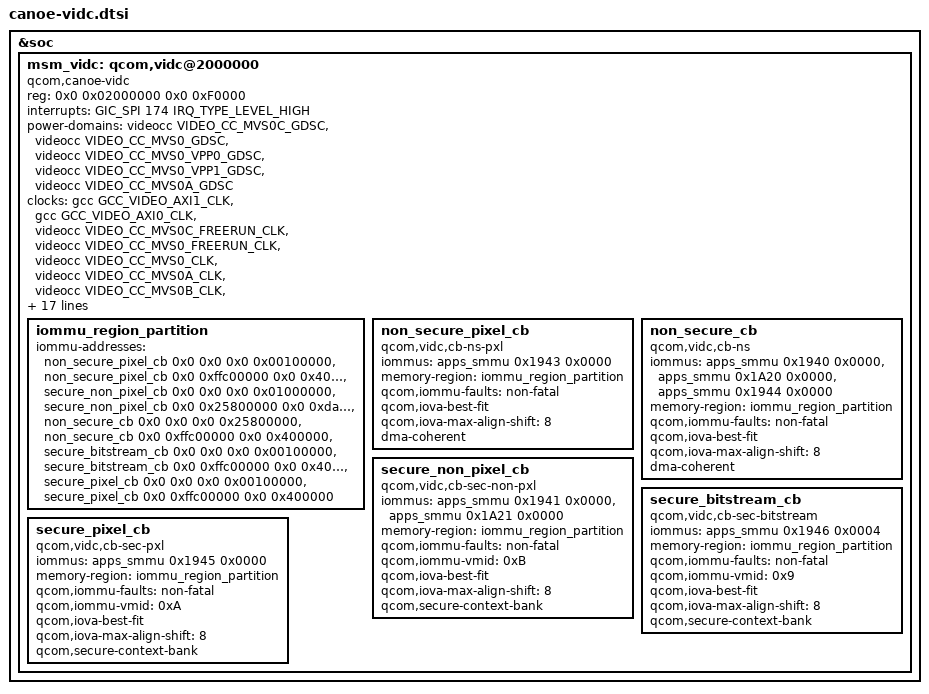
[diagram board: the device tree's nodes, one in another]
// SPDX-License-Identifier: BSD-3-Clause
/*
 * Copyright (c) 2024-2025 Qualcomm Innovation Center, Inc. All rights reserved.
 */

&soc {
	msm_vidc: qcom,vidc@2000000 {
		compatible = "qcom,canoe-vidc";
		status = "okay";

		/* IOMMU Config */
		#address-cells = <2>;
		#size-cells    = <2>;

		reg = <0x0 0x02000000 0x0 0xF0000>;
		interrupts = <GIC_SPI 174 IRQ_TYPE_LEVEL_HIGH>;

		/* Power Domains */
		power-domains = <&videocc VIDEO_CC_MVS0C_GDSC>,
				<&videocc VIDEO_CC_MVS0_GDSC>,
				<&videocc VIDEO_CC_MVS0_VPP0_GDSC>,
				<&videocc VIDEO_CC_MVS0_VPP1_GDSC>,
				<&videocc VIDEO_CC_MVS0A_GDSC>;
		power-domain-names = "iris-ctl", "vcodec", "vpp0", "vpp1", "apv";

		/* Clocks */
		clocks =
			 <&gcc GCC_VIDEO_AXI1_CLK>,
			 <&gcc GCC_VIDEO_AXI0_CLK>,
			 <&videocc VIDEO_CC_MVS0C_FREERUN_CLK>,
			 <&videocc VIDEO_CC_MVS0_FREERUN_CLK>,
			 <&videocc VIDEO_CC_MVS0_CLK>,
			 <&videocc VIDEO_CC_MVS0A_CLK>,
			 <&videocc VIDEO_CC_MVS0B_CLK>,
			 <&videocc VIDEO_CC_MVS0C_CLK>,
			 <&videocc VIDEO_CC_MVS0_VPP0_CLK>,
			 <&videocc VIDEO_CC_MVS0_VPP1_CLK>,
			 <&videocc VIDEO_CC_MVS0_CLK_SRC>,
			 <&videocc VIDEO_CC_MVS0A_CLK_SRC>,
			 <&videocc VIDEO_CC_MVS0B_CLK_SRC>,
			 <&videocc VIDEO_CC_MVS0C_CLK_SRC>;
		clock-names =
			 "gcc_video_axi1_clk",
			 "gcc_video_axi0_clk",
			 "video_cc_mvs0c_freerun_clk",
			 "video_cc_mvs0_freerun_clk",
			 "video_cc_mvs0_clk",
			 "video_cc_mvs0a_clk",
			 "video_cc_mvs0b_clk",
			 "video_cc_mvs0c_clk",
			 "video_cc_mvs0_vpp0_clk",
			 "video_cc_mvs0_vpp1_clk",
			 "video_cc_mvs0_clk_src",
			 "video_cc_mvs0a_clk_src",
			 "video_cc_mvs0b_clk_src",
			 "video_cc_mvs0c_clk_src";

		/* Bus Interconnects */
		interconnects =
			 <&gem_noc MASTER_APPSS_PROC &config_noc SLAVE_VENUS_CFG>,
			 <&mc_virt MASTER_LLCC &mc_virt SLAVE_EBI1>,
			 <&mmss_noc MASTER_VIDEO_MVP &gem_noc SLAVE_LLCC>;
		interconnect-names =
			 "venus-cnoc",
			 "venus-ddr",
			 "venus-llcc";

		/* FW load region */
		memory-region = <&video_mem>;

		/* Clock Resets */
		resets =
			 <&gcc GCC_VIDEO_AXI1_CLK_ARES>,
			 <&gcc GCC_VIDEO_AXI0_CLK_ARES>,
			 <&videocc VIDEO_CC_MVS0C_FREERUN_CLK_ARES>,
			 <&videocc VIDEO_CC_MVS0_FREERUN_CLK_ARES>;
		reset-names =
			 "video_axi1_reset",
			 "video_axi0_reset",
			 "video_mvs0c_freerun_reset",
			 "video_mvs0_freerun_reset";

		/* MMUs */
		iommu_region_partition: iommu_region_partition {
			/* These IOVA regions are unique per context bank */
			iommu-addresses =
				<&non_secure_pixel_cb 0x0 0x0 0x0 0x00100000>,
					<&non_secure_pixel_cb 0x0 0xffc00000 0x0 0x400000>,
				<&secure_non_pixel_cb 0x0 0x0 0x0 0x01000000>,
					<&secure_non_pixel_cb 0x0 0x25800000 0x0 0xda800000>,
				<&non_secure_cb       0x0 0x0 0x0 0x25800000>,
					<&non_secure_cb       0x0 0xffc00000  0x0 0x400000>,
				<&secure_bitstream_cb 0x0 0x0 0x0 0x00100000>,
					<&secure_bitstream_cb 0x0 0xffc00000 0x0 0x400000>,
				<&secure_pixel_cb     0x0 0x0 0x0 0x00100000>,
					<&secure_pixel_cb     0x0 0xffc00000 0x0 0x400000>;
		};

		non_secure_pixel_cb: non_secure_pixel_cb {
			compatible = "qcom,vidc,cb-ns-pxl";
			iommus = <&apps_smmu 0x1943 0x0000>;
			memory-region = <&iommu_region_partition>;
			qcom,iommu-faults = "non-fatal";
			qcom,iova-best-fit;
			/* log2 of desired alignment (1MB) - log2 of PAGE_SIZE; (8 = 20 - 12) */
			qcom,iova-max-align-shift = <8>;
			dma-coherent;
		};

		non_secure_cb: non_secure_cb {
			compatible = "qcom,vidc,cb-ns";
			iommus = <&apps_smmu 0x1940 0x0000>,
				 <&apps_smmu 0x1A20 0x0000>,
				 <&apps_smmu 0x1944 0x0000>;
			memory-region = <&iommu_region_partition>;
			qcom,iommu-faults = "non-fatal";
			qcom,iova-best-fit;
			qcom,iova-max-align-shift = <8>; /* 1 MB */
			dma-coherent;
		};

		secure_non_pixel_cb: secure_non_pixel_cb {
			compatible = "qcom,vidc,cb-sec-non-pxl";
			iommus = <&apps_smmu 0x1941 0x0000>,
					 <&apps_smmu 0x1A21 0x0000>;
			memory-region = <&iommu_region_partition>;
			qcom,iommu-faults = "non-fatal";
			qcom,iommu-vmid = <0xB>; /* VMID_CP_NON_PIXEL */
			qcom,iova-best-fit;
			qcom,iova-max-align-shift = <8>; /* 1 MB */
			qcom,secure-context-bank;
		};

		secure_bitstream_cb: secure_bitstream_cb {
			compatible = "qcom,vidc,cb-sec-bitstream";
			iommus = <&apps_smmu 0x1946 0x0004>;
			memory-region = <&iommu_region_partition>;
			qcom,iommu-faults = "non-fatal";
			qcom,iommu-vmid = <0x9>; /* VMID_CP_BITSTREAM */
			qcom,iova-best-fit;
			qcom,iova-max-align-shift = <8>; /* 1 MB */
			qcom,secure-context-bank;
		};

		secure_pixel_cb: secure_pixel_cb {
			compatible = "qcom,vidc,cb-sec-pxl";
			iommus = <&apps_smmu 0x1945 0x0000>;
			memory-region = <&iommu_region_partition>;
			qcom,iommu-faults = "non-fatal";
			qcom,iommu-vmid = <0xA>; /* VMID_CP_PIXEL */
			qcom,iova-best-fit;
			qcom,iova-max-align-shift = <8>; /* 1 MB */
			qcom,secure-context-bank;
		};
	};
};
